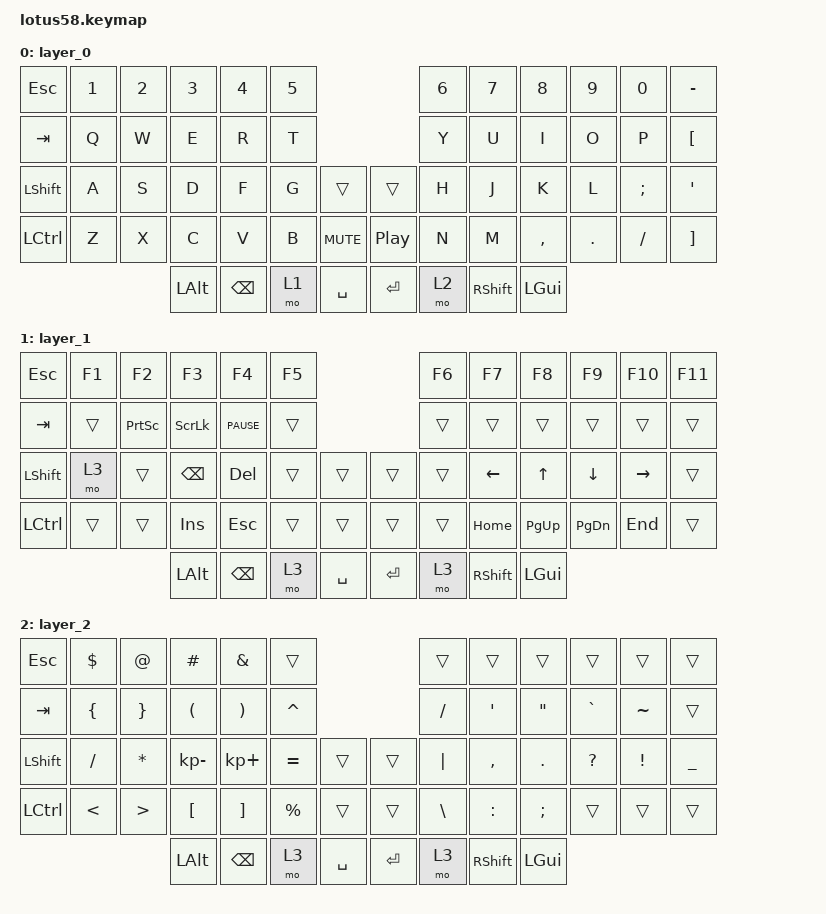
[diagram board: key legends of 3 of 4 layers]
/*
 * Copyright (c) 2022 The ZMK Contributors
 *
 * SPDX-License-Identifier: MIT
 */

#include <behaviors.dtsi>
#include <dt-bindings/zmk/keys.h>
#include <dt-bindings/zmk/bt.h>
#include <dt-bindings/zmk/outputs.h>
#include <dt-bindings/zmk/rgb.h>
#include <dt-bindings/led/led.h>

&i2c0 {
    status = "okay";
    ssd1306: ssd1306@3c {
        compatible = "solomon,ssd1306fb";
        reg = <0x3c>;
        label = "SSD1306";
        width = <128>;
        height = <64>;
        page-offset = <0>;
        display-offset = <0>;
        prechargep = <0xF1>;
        multiplex-ratio = <63>;
    };
};


//---------------------------------------------------
&pinctrl {
    spi3_default: spi3_default {
        group1 {
            psels = <NRF_PSEL(SPIM_MOSI, 0, 6)>;
        };
    };

    spi3_sleep: spi3_sleep {
        group1 {
            psels = <NRF_PSEL(SPIM_MOSI, 0, 6)>;
            low-power-enable;
        };
    };
};

&spi3 {
    compatible = "nordic,nrf-spim";
    status = "okay";

    pinctrl-0 = <&spi3_default>;
    pinctrl-1 = <&spi3_sleep>;
    pinctrl-names = "default", "sleep";

    led_strip: ws2812@0 {
        compatible = "worldsemi,ws2812-spi";

        /* SPI */
        reg = <0>; /* ignored, but necessary for SPI bindings */
        spi-max-frequency = <4000000>;

        /* WS2812 */
        chain-length = <29>; /* arbitrary; change at will */
        spi-one-frame = <0x70>;
        spi-zero-frame = <0x40>;

        color-mapping = <LED_COLOR_ID_GREEN LED_COLOR_ID_RED LED_COLOR_ID_BLUE>;
    };
};

/ {
    chosen {
        zmk,underglow = &led_strip;
    };
};

//----------------------------------------------------------------

/ {
    combos {
        compatible = "zmk,combos";
        combo_dsklg {
            timeout-ms = <100>;
            key-positions = <24 52>;
            layers = <0>;
            bindings = <&kp LGUI>;
        };
    };

    behaviors {
        fofunc: four_ffour {
            compatible = "zmk,behavior-mod-morph";
            #binding-cells = <0>;
            bindings = <&kp N4>, <&kp F4>;
            mods = <(MOD_LALT|MOD_RALT)>;
        };
        sleft: s_left {
            compatible = "zmk,behavior-mod-morph";
            #binding-cells = <0>;
            bindings = <&kp S>, <&kp LEFT>;
            mods = <(MOD_LGUI|MOD_RGUI)>;
        };
        fright: f_right {
            compatible = "zmk,behavior-mod-morph";
            #binding-cells = <0>;
            bindings = <&kp F>, <&kp RIGHT>;
            mods = <(MOD_LGUI|MOD_RGUI)>;
        };

        rgb_encoder: rgb_encoder {
            compatible = "zmk,behavior-sensor-rotate";
            #sensor-binding-cells = <0>;
            bindings = <&rgb_ug RGB_BRI>, <&rgb_ug RGB_BRD>;
        };
    };

    keymap {
        compatible = "zmk,keymap";

        layer_0 {
            bindings = <
&kp ESC   &kp N1 &kp N2   &kp N3     &kp N4    &kp N5                               &kp N6    &kp N7      &kp N8    &kp N9   &kp N0   &kp MINUS
&kp TAB   &kp Q  &kp W    &kp E      &kp R     &kp T                                &kp Y     &kp U       &kp I     &kp O    &kp P    &kp LEFT_BRACKET
&kp LSHFT &kp A  &kp S    &kp D      &kp F     &kp G      &trans         &trans     &kp H     &kp J       &kp K     &kp L    &kp SEMI &kp SINGLE_QUOTE
&kp LCTRL &kp Z  &kp X    &kp C      &kp V     &kp B      &kp K_MUTE     &kp C_PP   &kp N     &kp M       &kp COMMA &kp DOT  &kp SLASH &kp RIGHT_BRACKET
                          &kp LALT   &kp BSPC  &mo 1 &kp SPACE     &kp ENTER  &mo 2  &kp RSHIFT  &kp LEFT_GUI
            >;

            sensor-bindings = <&inc_dec_kp K_VOL_DN K_VOL_UP>, <&inc_dec_kp K_VOL_DN K_VOL_UP>;
        };

         layer_1 {
            bindings = <
&kp ESC   &kp F1    &kp F2    &kp F3    &kp F4    &kp F5                                &kp F6    &kp F7    &kp F8    &kp F9    &kp F10   &kp F11
&kp TAB   &trans    &kp PSCRN &kp SLCK  &kp C_PAUSE &trans                                &trans    &trans    &trans    &trans    &trans    &trans
&kp LSHFT &mo 3     &trans    &kp BSPC  &kp DELETE &trans   &trans            &trans    &trans    &kp LEFT  &kp UP    &kp DOWN  &kp RIGHT &trans
&kp LCTRL &trans    &trans    &kp INSERT &kp ESCAPE &trans  &trans            &trans    &trans    &kp HOME  &kp PAGE_UP &kp PAGE_DOWN &kp END &trans
                              &kp LALT  &kp BSPC  &mo 3     &kp SPACE         &kp ENTER &mo 3     &kp RSHIFT &kp LEFT_GUI
            >;

            sensor-bindings = <&inc_dec_kp C_VOL_DN C_VOL_UP &inc_dec_kp C_NEXT C_PREV>;
        };

        layer_2 {
            bindings = <
&kp ESC   &kp DLLR     &kp AT      &kp HASH        &kp AMPS       &trans                                   &trans       &trans              &trans        &trans       &trans       &trans
&kp TAB   &kp LBRC     &kp RBRC    &kp LPAR        &kp RPAR       &kp CARET                                &kp SLASH    &kp SINGLE_QUOTE    &kp DQT       &kp GRAVE    &kp TILDE    &trans
&kp LSHFT &kp FSLH     &kp STAR    &kp KP_MINUS    &kp KP_PLUS    &kp EQUAL    &trans            &trans    &kp PIPE     &kp COMMA           &kp PERIOD    &kp QMARK    &kp EXCL     &kp UNDER
&kp LCTRL &kp LT       &kp GT      &kp LBKT        &kp RBKT       &kp PERCENT  &trans            &trans    &kp BSLH     &kp COLON           &kp SEMI      &trans       &trans       &trans
                           &kp LALT  &kp BSPC   &mo 3                          &kp SPACE         &kp ENTER         &mo 3     &kp RSHIFT &kp LEFT_GUI
            >;

            sensor-bindings = <&inc_dec_kp C_VOL_DN C_VOL_UP &inc_dec_kp PG_UP PG_DN>;
        };  

        layer_3 {
            bindings = <
&out OUT_TOG    &trans    &trans    &rgb_ug RGB_EFF &rgb_ug RGB_HUD  &rgb_ug RGB_HUI                                &bt BT_SEL 0   &bt BT_SEL 1    &bt BT_SEL 2    &trans    &trans    &bt BT_CLR
&trans          &trans    &trans    &rgb_ug RGB_EFR &rgb_ug RGB_SAD  &rgb_ug RGB_SAI                                &trans         &trans          &trans          &trans    &trans    &trans
&trans          &trans    &trans    &trans          &rgb_ug RGB_BRD  &rgb_ug RGB_BRI    &trans            &trans    &trans         &trans          &trans          &trans    &trans    &trans
&trans          &trans    &trans    &rgb_ug RGB_TOG &rgb_ug RGB_SPD  &rgb_ug RGB_SPI    &trans            &trans    &trans         &trans          &trans          &trans    &trans    &trans
                    &trans    &trans        &trans        &trans        &trans            &trans    &trans    &trans    &trans    &trans
            >;

            sensor-bindings = <&rgb_encoder &inc_dec_kp C_NEXT C_PREV>;
        };
    };
};
